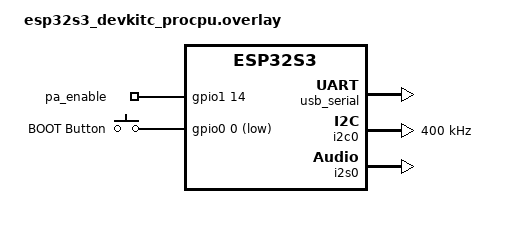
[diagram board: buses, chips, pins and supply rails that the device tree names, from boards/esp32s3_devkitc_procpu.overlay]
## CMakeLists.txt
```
cmake_minimum_required(VERSION 3.20.0)
find_package(Zephyr REQUIRED HINTS $ENV{ZEPHYR_BASE})
project(voice_assistant)

target_sources(app PRIVATE
    src/main.c
    src/audio.c
    src/base64.c
)
```

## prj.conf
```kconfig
# ── Console ──
CONFIG_PRINTK=y
CONFIG_CONSOLE=y
CONFIG_SERIAL=y
CONFIG_LOG=y
CONFIG_LOG_DEFAULT_LEVEL=3
CONFIG_LOG_BUFFER_SIZE=8192

# ── GPIO (PA enable + BOOT button) ──
CONFIG_GPIO=y

# ── I2C (ES8311 + ES7210 register config) ──
CONFIG_I2C=y

# ── I2S (audio TX/RX) + DMA ──
CONFIG_I2S=y
CONFIG_DMA=y

# ── Networking ──
CONFIG_NETWORKING=y
CONFIG_NET_MGMT=y
CONFIG_NET_MGMT_EVENT_INFO=y
CONFIG_NET_IPV4=y
CONFIG_NET_IPV6=n
CONFIG_NET_TCP=y
CONFIG_NET_DHCPV4=y
CONFIG_NET_SOCKETS=y
CONFIG_POSIX_API=y

# ── WiFi ──
CONFIG_WIFI=y
CONFIG_WIFI_NM=y
CONFIG_NET_L2_WIFI_MGMT=y
CONFIG_ESP32_WIFI_STA_AUTO_DHCPV4=y

# ── DNS ──
CONFIG_DNS_RESOLVER=y
CONFIG_DNS_RESOLVER_AI_MAX_ENTRIES=2

# ── HTTP client ──
CONFIG_HTTP_CLIENT=y

# ── TLS / mbedTLS ──
CONFIG_MBEDTLS=y
CONFIG_MBEDTLS_BUILTIN=y
CONFIG_MBEDTLS_ENABLE_HEAP=y
CONFIG_MBEDTLS_HEAP_SIZE=65536
CONFIG_MBEDTLS_SSL_MAX_CONTENT_LEN=16384
CONFIG_MBEDTLS_CIPHER_GCM_ENABLED=y
CONFIG_MBEDTLS_KEY_EXCHANGE_ECDHE_RSA_ENABLED=y
CONFIG_MBEDTLS_KEY_EXCHANGE_RSA_ENABLED=y
CONFIG_MBEDTLS_ECP_DP_SECP256R1_ENABLED=y
CONFIG_MBEDTLS_ECP_DP_SECP384R1_ENABLED=y
CONFIG_MBEDTLS_ECDH_C=y
CONFIG_MBEDTLS_ECP_C=y
CONFIG_NET_SOCKETS_SOCKOPT_TLS=y
CONFIG_NET_SOCKETS_TLS_MAX_CONTEXTS=2
# SNI + GCM required by Alibaba Cloud CDN
CONFIG_MBEDTLS_SERVER_NAME_INDICATION=y

# ── Stack & buffers ──
CONFIG_MAIN_STACK_SIZE=12288
CONFIG_SYSTEM_WORKQUEUE_STACK_SIZE=4096
CONFIG_NET_TX_STACK_SIZE=2048
CONFIG_NET_RX_STACK_SIZE=2048
CONFIG_NET_PKT_RX_COUNT=16
CONFIG_NET_PKT_TX_COUNT=16
CONFIG_NET_BUF_RX_COUNT=64
CONFIG_NET_BUF_TX_COUNT=64
CONFIG_NET_MAX_CONTEXTS=8
CONFIG_NET_MGMT_EVENT_QUEUE_TIMEOUT=5000
CONFIG_NET_MGMT_EVENT_QUEUE_SIZE=16

# ── Heap ──
CONFIG_HEAP_MEM_POOL_SIZE=32768
```

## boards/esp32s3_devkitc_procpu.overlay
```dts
/* Voice Assistant: ES8311 DAC + ES7210 ADC + PA + BOOT Button + USB Console
 *
 * I2C0 — ES8311 (0x18) + ES7210 (0x40) register config (SCL=IO18, SDA=IO8)
 * I2S0 — Audio TX (speaker via ES8311) + RX (mic via ES7210)
 *         MCLK=IO2, BCLK=IO17, WS=IO45, DOUT=IO15, DIN=IO16
 * PA   — GPIO46 (gpio1 pin 14), active-high
 * BOOT — GPIO0 (gpio0 pin 0), active-low, push-to-talk
 */

#include <zephyr/dt-bindings/pinctrl/esp32s3-pinctrl.h>
#include <zephyr/dt-bindings/pinctrl/esp-pinctrl-common.h>
#include <dt-bindings/pinctrl/esp32s3-pinctrl.h>
#include <zephyr/dt-bindings/pinctrl/esp32s3-gpio-sigmap.h>

/ {
	chosen {
		zephyr,console = &usb_serial;
		zephyr,shell-uart = &usb_serial;
	};

	leds {
		compatible = "gpio-leds";
		pa_enable: pa {
			gpios = <&gpio1 14 GPIO_ACTIVE_HIGH>;
		};
	};

	buttons {
		compatible = "gpio-keys";
		boot_button: boot_button {
			gpios = <&gpio0 0 (GPIO_PULL_UP | GPIO_ACTIVE_LOW)>;
			label = "BOOT Button";
		};
	};

	aliases {
		sw0 = &boot_button;
	};
};

&usb_serial {
	status = "okay";
};

&pinctrl {
	i2c0_default: i2c0_default {
		group1 {
			pinmux = <I2C0_SDA_GPIO8>,
				 <I2C0_SCL_GPIO18>;
			bias-pull-up;
			drive-open-drain;
			output-high;
		};
	};

	i2s0_default: i2s0_default {
		group1 {
			pinmux = <I2S0_MCLK_GPIO2>,
				 <I2S0_O_WS_GPIO45>,
				 <I2S0_O_BCK_GPIO17>,
				 <I2S0_O_SD_GPIO15>;
			output-enable;
		};
		group2 {
			pinmux = <I2S0_I_SD_GPIO16>;
			input-enable;
		};
	};
};

&i2c0 {
	status = "okay";
	clock-frequency = <I2C_BITRATE_FAST>;
	pinctrl-0 = <&i2c0_default>;
	pinctrl-names = "default";
};

i2s_rxtx: &i2s0 {
	pinctrl-0 = <&i2s0_default>;
	pinctrl-names = "default";
	status = "okay";
};

&dma {
	status = "okay";
};
```

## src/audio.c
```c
/*
 * audio.c — ES8311 DAC + ES7210 ADC initialization, I2S record & playback
 *
 * ES8311 (0x18): DAC for speaker output via I2S TX
 * ES7210 (0x40): ADC for microphone input via I2S RX
 * I2S0: shared bus, master mode (generates MCLK/BCLK/WS)
 * PA: GPIO46 (gpio1 pin 14), controls speaker amplifier
 */

#include <zephyr/kernel.h>
#include <zephyr/device.h>
#include <zephyr/drivers/i2c.h>
#include <zephyr/drivers/i2s.h>
#include <zephyr/drivers/gpio.h>
#include <zephyr/logging/log.h>
#include <string.h>

#include "audio.h"

LOG_MODULE_REGISTER(audio, LOG_LEVEL_INF);

/* ── ES8311 registers ── */
#define ES8311_ADDR              0x18
#define ES8311_RESET_REG00       0x00
#define ES8311_CLK_MANAGER_REG01 0x01
#define ES8311_CLK_MANAGER_REG02 0x02
#define ES8311_CLK_MANAGER_REG03 0x03
#define ES8311_CLK_MANAGER_REG04 0x04
#define ES8311_CLK_MANAGER_REG05 0x05
#define ES8311_CLK_MANAGER_REG06 0x06
#define ES8311_CLK_MANAGER_REG07 0x07
#define ES8311_CLK_MANAGER_REG08 0x08
#define ES8311_SDPIN_REG09       0x09
#define ES8311_SDPOUT_REG0A      0x0A
#define ES8311_SYSTEM_REG0D      0x0D
#define ES8311_SYSTEM_REG0E      0x0E
#define ES8311_SYSTEM_REG12      0x12
#define ES8311_SYSTEM_REG13      0x13
#define ES8311_ADC_REG16         0x16
#define ES8311_ADC_REG1C         0x1C
#define ES8311_DAC_REG31         0x31
#define ES8311_DAC_REG32         0x32
#define ES8311_DAC_REG37         0x37
#define ES8311_CHIPID1_REG_FD    0xFD
#define ES8311_CHIPID2_REG_FE    0xFE

/* ── ES7210 registers ── */
#define ES7210_ADDR                 0x40
#define ES7210_RESET_REG00          0x00
#define ES7210_CLOCK_OFF_REG01      0x01
#define ES7210_MAINCLK_REG02        0x02
#define ES7210_LRCK_DIVH_REG04      0x04
#define ES7210_LRCK_DIVL_REG05      0x05
#define ES7210_POWER_DOWN_REG06     0x06
#define ES7210_OSR_REG07            0x07
#define ES7210_TIME_CONTROL0_REG09  0x09
#define ES7210_TIME_CONTROL1_REG0A  0x0A
#define ES7210_SDP_INTERFACE1_REG11 0x11
#define ES7210_SDP_INTERFACE2_REG12 0x12
#define ES7210_ADC12_HPF2_REG22     0x22
#define ES7210_ADC12_HPF1_REG23     0x23
#define ES7210_ADC34_HPF2_REG20     0x20
#define ES7210_ADC34_HPF1_REG21     0x21
#define ES7210_ANALOG_REG40         0x40
#define ES7210_MIC12_BIAS_REG41     0x41
#define ES7210_MIC34_BIAS_REG42     0x42
#define ES7210_MIC1_GAIN_REG43      0x43
#define ES7210_MIC2_GAIN_REG44      0x44
#define ES7210_MIC3_GAIN_REG45      0x45
#define ES7210_MIC4_GAIN_REG46      0x46
#define ES7210_MIC1_POWER_REG47     0x47
#define ES7210_MIC2_POWER_REG48     0x48
#define ES7210_MIC3_POWER_REG49     0x49
#define ES7210_MIC4_POWER_REG4A     0x4A
#define ES7210_MIC12_POWER_REG4B    0x4B
#define ES7210_MIC34_POWER_REG4C    0x4C

/* ── I2S config ── */
#define I2S_NODE          DT_NODELABEL(i2s_rxtx)
#define SAMPLES_PER_BLOCK ((RECORD_SAMPLE_RATE / 100) * NUM_CHANNELS)  /* 320 */
#define BLOCK_SIZE        (SAMPLES_PER_BLOCK * sizeof(int16_t))        /* 640 */
#define BLOCK_COUNT       12

K_MEM_SLAB_DEFINE_STATIC(tx_mem_slab, BLOCK_SIZE, BLOCK_COUNT, 4);
K_MEM_SLAB_DEFINE_STATIC(rx_mem_slab, BLOCK_SIZE, BLOCK_COUNT, 4);

/* ── PA GPIO ── */
static const struct gpio_dt_spec pa_gpio =
	GPIO_DT_SPEC_GET(DT_NODELABEL(pa_enable), gpios);

/* ── Devices ── */
static const struct device *i2c_dev;
static const struct device *i2s_dev;

/* ── I2C helpers ── */
static int es8311_write_reg(uint8_t reg, uint8_t val)
{
	uint8_t buf[2] = {reg, val};
	return i2c_write(i2c_dev, buf, 2, ES8311_ADDR);
}

static int es7210_write_reg(uint8_t reg, uint8_t val)
{
	uint8_t buf[2] = {reg, val};
	return i2c_write(i2c_dev, buf, 2, ES7210_ADDR);
}

/* ── ES8311 init: 16kHz, 16-bit, I2S slave, MCLK=4.096MHz ── */
static int es8311_init(void)
{
	int ret;

	/* Reset — must go through 0x1F → 0x00 → 0x80 sequence */
	ret = es8311_write_reg(ES8311_RESET_REG00, 0x1F);
	if (ret) return ret;
	k_msleep(20);
	ret = es8311_write_reg(ES8311_RESET_REG00, 0x00);
	if (ret) return ret;
	k_msleep(20);
	ret = es8311_write_reg(ES8311_RESET_REG00, 0x80);
	if (ret) return ret;

	/* Clock config — match known-working es8311_test/nes_emulator values
	 * MCLK from external pin, BCLK from MCLK, dividers for 16kHz */
	ret = es8311_write_reg(ES8311_CLK_MANAGER_REG01, 0x3F);
	if (ret) return ret;
	ret = es8311_write_reg(ES8311_CLK_MANAGER_REG02, 0x00);
	if (ret) return ret;
	ret = es8311_write_reg(ES8311_CLK_MANAGER_REG03, 0x10);
	if (ret) return ret;
	ret = es8311_write_reg(ES8311_CLK_MANAGER_REG04, 0x10);
	if (ret) return ret;
	ret = es8311_write_reg(ES8311_CLK_MANAGER_REG05, 0x00);
	if (ret) return ret;
	ret = es8311_write_reg(ES8311_ADC_REG16, 0x24);
	if (ret) return ret;
	ret = es8311_write_reg(ES8311_CLK_MANAGER_REG06, 0x03);
	if (ret) return ret;
	ret = es8311_write_reg(ES8311_CLK_MANAGER_REG07, 0x00);
	if (ret) return ret;
	ret = es8311_write_reg(ES8311_CLK_MANAGER_REG08, 0xFF);
	if (ret) return ret;

	/* I2S format: slave mode, 16-bit */
	ret = es8311_write_reg(ES8311_SDPIN_REG09, 0x0C);
	if (ret) return ret;
	ret = es8311_write_reg(ES8311_SDPOUT_REG0A, 0x0C);
	if (ret) return ret;

	/* Power up analog */
	ret = es8311_write_reg(ES8311_SYSTEM_REG0D, 0x01);
	if (ret) return ret;
	ret = es8311_write_reg(ES8311_SYSTEM_REG0E, 0x02);
	if (ret) return ret;
	ret = es8311_write_reg(ES8311_SYSTEM_REG12, 0x00);
	if (ret) return ret;
	ret = es8311_write_reg(ES8311_SYSTEM_REG13, 0x10);
	if (ret) return ret;

	/* ADC EQ bypass, cancel DC offset */
	ret = es8311_write_reg(ES8311_ADC_REG1C, 0x6A);
	if (ret) return ret;

	/* Bypass DAC equalizer */
	ret = es8311_write_reg(ES8311_DAC_REG37, 0x08);
	if (ret) return ret;

	/* DAC volume ~80% */
	ret = es8311_write_reg(ES8311_DAC_REG32, 0xC0);
	if (ret) return ret;

	/* Unmute DAC */
	ret = es8311_write_reg(ES8311_DAC_REG31, 0x00);
	if (ret) return ret;

	return 0;
}

/* ── ES7210 init: 16kHz, 16-bit, 4-ch ADC, MIC gain 30dB ── */
static int es7210_init(void)
{
	int ret;

	/* Software reset */
	ret = es7210_write_reg(ES7210_RESET_REG00, 0xFF);
	if (ret) return ret;
	ret = es7210_write_reg(ES7210_RESET_REG00, 0x32);
	if (ret) return ret;

	/* Power-up timing */
	ret = es7210_write_reg(ES7210_TIME_CONTROL0_REG09, 0x30);
	if (ret) return ret;
	ret = es7210_write_reg(ES7210_TIME_CONTROL1_REG0A, 0x30);
	if (ret) return ret;

	/* HPF config */
	ret = es7210_write_reg(ES7210_ADC12_HPF1_REG23, 0x2A);
	if (ret) return ret;
	ret = es7210_write_reg(ES7210_ADC12_HPF2_REG22, 0x0A);
	if (ret) return ret;
	ret = es7210_write_reg(ES7210_ADC34_HPF1_REG21, 0x2A);
	if (ret) return ret;
	ret = es7210_write_reg(ES7210_ADC34_HPF2_REG20, 0x0A);
	if (ret) return ret;

	/* I2S format: 16-bit, standard I2S */
	ret = es7210_write_reg(ES7210_SDP_INTERFACE1_REG11, 0x60);
	if (ret) return ret;
	ret = es7210_write_reg(ES7210_SDP_INTERFACE2_REG12, 0x00);
	if (ret) return ret;

	/* Analog power */
	ret = es7210_write_reg(ES7210_ANALOG_REG40, 0xC3);
	if (ret) return ret;

	/* MIC bias 2.87V */
	ret = es7210_write_reg(ES7210_MIC12_BIAS_REG41, 0x70);
	if (ret) return ret;
	ret = es7210_write_reg(ES7210_MIC34_BIAS_REG42, 0x70);
	if (ret) return ret;

	/* MIC gain 30dB */
	ret = es7210_write_reg(ES7210_MIC1_GAIN_REG43, 0x1A);
	if (ret) return ret;
	ret = es7210_write_reg(ES7210_MIC2_GAIN_REG44, 0x1A);
	if (ret) return ret;
	ret = es7210_write_reg(ES7210_MIC3_GAIN_REG45, 0x1A);
	if (ret) return ret;
	ret = es7210_write_reg(ES7210_MIC4_GAIN_REG46, 0x1A);
	if (ret) return ret;

	/* Power on MIC1-4 */
	ret = es7210_write_reg(ES7210_MIC1_POWER_REG47, 0x08);
	if (ret) return ret;
	ret = es7210_write_reg(ES7210_MIC2_POWER_REG48, 0x08);
	if (ret) return ret;
	ret = es7210_write_reg(ES7210_MIC3_POWER_REG49, 0x08);
	if (ret) return ret;
	ret = es7210_write_reg(ES7210_MIC4_POWER_REG4A, 0x08);
	if (ret) return ret;

	/* Clock: MCLK=4096000, fs=16000 */
	ret = es7210_write_reg(ES7210_OSR_REG07, 0x20);
	if (ret) return ret;
	ret = es7210_write_reg(ES7210_MAINCLK_REG02, 0xC1);
	if (ret) return ret;
	ret = es7210_write_reg(ES7210_LRCK_DIVH_REG04, 0x01);
	if (ret) return ret;
	ret = es7210_write_reg(ES7210_LRCK_DIVL_REG05, 0x00);
	if (ret) return ret;

	/* Power down DLL */
	ret = es7210_write_reg(ES7210_POWER_DOWN_REG06, 0x04);
	if (ret) return ret;

	/* Power on MIC bias & ADC & PGA */
	ret = es7210_write_reg(ES7210_MIC12_POWER_REG4B, 0x0F);
	if (ret) return ret;
	ret = es7210_write_reg(ES7210_MIC34_POWER_REG4C, 0x0F);
	if (ret) return ret;

	/* Enable device */
	ret = es7210_write_reg(ES7210_RESET_REG00, 0x71);
	if (ret) return ret;
	ret = es7210_write_reg(ES7210_RESET_REG00, 0x41);
	if (ret) return ret;

	return 0;
}

/* ================================================================
 *  Public API
 * ================================================================ */

/* ── I2S configured once flag ── */
static bool i2s_configured;

int audio_codec_init(void)
{
	int ret;

	/* I2C */
	i2c_dev = DEVICE_DT_GET(DT_NODELABEL(i2c0));
	if (!device_is_ready(i2c_dev)) {
		LOG_ERR("I2C device not ready");
		return -ENODEV;
	}

	/* I2S */
	i2s_dev = DEVICE_DT_GET(I2S_NODE);
	if (!device_is_ready(i2s_dev)) {
		LOG_ERR("I2S device not ready");
		return -ENODEV;
	}

	/* ES8311 DAC */
	ret = es8311_init();
	if (ret) {
		LOG_ERR("ES8311 init failed: %d", ret);
		return ret;
	}
	LOG_INF("ES8311 DAC initialized");

	/* ES7210 ADC */
	ret = es7210_init();
	if (ret) {
		LOG_ERR("ES7210 init failed: %d", ret);
		return ret;
	}
	LOG_INF("ES7210 ADC initialized");

	/* PA GPIO */
	if (!gpio_is_ready_dt(&pa_gpio)) {
		LOG_ERR("PA GPIO not ready");
		return -ENODEV;
	}
	ret = gpio_pin_configure_dt(&pa_gpio, GPIO_OUTPUT_INACTIVE);
	if (ret) {
		LOG_ERR("PA GPIO config failed: %d", ret);
		return ret;
	}

	/* Configure I2S TX + RX once — both share 16kHz, 16-bit, stereo */
	struct i2s_config tx_cfg = {
		.word_size = SAMPLE_BITS,
		.channels = NUM_CHANNELS,
		.format = I2S_FMT_DATA_FORMAT_I2S,
		.options = I2S_OPT_BIT_CLK_MASTER | I2S_OPT_FRAME_CLK_MASTER,
		.frame_clk_freq = RECORD_SAMPLE_RATE,
		.mem_slab = &tx_mem_slab,
		.block_size = BLOCK_SIZE,
		.timeout = 1000,
	};
	ret = i2s_configure(i2s_dev, I2S_DIR_TX, &tx_cfg);
	if (ret) {
		LOG_ERR("I2S TX config failed: %d", ret);
		return ret;
	}

	struct i2s_config rx_cfg = {
		.word_size = SAMPLE_BITS,
		.channels = NUM_CHANNELS,
		.format = I2S_FMT_DATA_FORMAT_I2S,
		.options = I2S_OPT_BIT_CLK_MASTER | I2S_OPT_FRAME_CLK_MASTER,
		.frame_clk_freq = RECORD_SAMPLE_RATE,
		.mem_slab = &rx_mem_slab,
		.block_size = BLOCK_SIZE,
		.timeout = 2000,
	};
	ret = i2s_configure(i2s_dev, I2S_DIR_RX, &rx_cfg);
	if (ret) {
		LOG_ERR("I2S RX config failed: %d", ret);
		return ret;
	}

	i2s_configured = true;
	LOG_INF("Audio codecs ready (16kHz, 16-bit)");
	return 0;
}

void audio_pa_enable(int on)
{
	gpio_pin_set_dt(&pa_gpio, on ? 1 : 0);
}

int audio_record(int16_t *pcm_buf, int max_samples, volatile bool *stop_flag)
{
	int ret;
	int mono_idx = 0;

	/* Full I2S reset sequence — critical for preventing DMA crashes
	 * after play→record transitions on ESP32-S3 */
	i2s_trigger(i2s_dev, I2S_DIR_TX, I2S_TRIGGER_PREPARE);  /* recover from ERROR if needed */
	i2s_trigger(i2s_dev, I2S_DIR_RX, I2S_TRIGGER_PREPARE);
	i2s_trigger(i2s_dev, I2S_DIR_RX, I2S_TRIGGER_DROP);
	i2s_trigger(i2s_dev, I2S_DIR_TX, I2S_TRIGGER_DROP);
	k_msleep(100);

	/* Reinitialize mem slabs — repairs any DMA-related free list corruption */
	k_mem_slab_init(&tx_mem_slab, tx_mem_slab.buffer, BLOCK_SIZE, BLOCK_COUNT);
	k_mem_slab_init(&rx_mem_slab, rx_mem_slab.buffer, BLOCK_SIZE, BLOCK_COUNT);

	/* Re-configure both directions (resets DMA descriptors) */
	struct i2s_config tx_cfg = {
		.word_size = SAMPLE_BITS,
		.channels = NUM_CHANNELS,
		.format = I2S_FMT_DATA_FORMAT_I2S,
		.options = I2S_OPT_BIT_CLK_MASTER | I2S_OPT_FRAME_CLK_MASTER,
		.frame_clk_freq = RECORD_SAMPLE_RATE,
		.mem_slab = &tx_mem_slab,
		.block_size = BLOCK_SIZE,
		.timeout = 1000,
	};
	ret = i2s_configure(i2s_dev, I2S_DIR_TX, &tx_cfg);
	if (ret && ret != -EBUSY) {
		LOG_ERR("I2S TX reconfig failed: %d", ret);
	}

	struct i2s_config rx_cfg = {
		.word_size = SAMPLE_BITS,
		.channels = NUM_CHANNELS,
		.format = I2S_FMT_DATA_FORMAT_I2S,
		.options = I2S_OPT_BIT_CLK_MASTER | I2S_OPT_FRAME_CLK_MASTER,
		.frame_clk_freq = RECORD_SAMPLE_RATE,
		.mem_slab = &rx_mem_slab,
		.block_size = BLOCK_SIZE,
		.timeout = 2000,
	};
	ret = i2s_configure(i2s_dev, I2S_DIR_RX, &rx_cfg);
	if (ret && ret != -EBUSY) {
		LOG_ERR("I2S RX reconfig failed: %d", ret);
	}

	/* Additional settle time for DMA hardware */
	k_msleep(50);

	/* Pre-fill TX with silence for clock generation */
	for (int i = 0; i < 2; i++) {
		void *blk;
		ret = k_mem_slab_alloc(&tx_mem_slab, &blk, K_NO_WAIT);
		if (ret) {
			LOG_ERR("TX block alloc failed");
			return ret;
		}
		memset(blk, 0, BLOCK_SIZE);
		ret = i2s_write(i2s_dev, blk, BLOCK_SIZE);
		if (ret) {
			LOG_ERR("I2S TX write failed: %d", ret);
			return ret;
		}
	}

	/* Start TX then RX */
	ret = i2s_trigger(i2s_dev, I2S_DIR_TX, I2S_TRIGGER_START);
	if (ret) {
		LOG_ERR("I2S TX start failed: %d", ret);
		return ret;
	}
	ret = i2s_trigger(i2s_dev, I2S_DIR_RX, I2S_TRIGGER_START);
	if (ret) {
		LOG_ERR("I2S RX start failed: %d", ret);
		return ret;
	}

	LOG_INF("Recording started...");

	/* Read blocks until stop_flag or max_samples reached */
	while (!(*stop_flag) && mono_idx < max_samples) {
		void *rx_blk;
		size_t rx_sz;
		void *tx_blk;

		/* Feed TX with silence to keep clocks running */
		if (k_mem_slab_alloc(&tx_mem_slab, &tx_blk, K_NO_WAIT) == 0) {
			memset(tx_blk, 0, BLOCK_SIZE);
			if (i2s_write(i2s_dev, tx_blk, BLOCK_SIZE) < 0) {
				k_mem_slab_free(&tx_mem_slab, tx_blk);
			}
		}

		/* Read one block of stereo data */
		ret = i2s_read(i2s_dev, &rx_blk, &rx_sz);
		if (ret) {
			LOG_WRN("I2S read error: %d", ret);
			break;
		}

		/* Extract left channel (mono) from interleaved stereo */
		int16_t *stereo = (int16_t *)rx_blk;
		int stereo_samples = rx_sz / sizeof(int16_t);
		for (int i = 0; i < stereo_samples && mono_idx < max_samples; i += 2) {
			pcm_buf[mono_idx++] = stereo[i];  /* left channel */
		}

		k_mem_slab_free(&rx_mem_slab, rx_blk);
	}

	/* Stop I2S */
	i2s_trigger(i2s_dev, I2S_DIR_RX, I2S_TRIGGER_DROP);
	i2s_trigger(i2s_dev, I2S_DIR_TX, I2S_TRIGGER_DROP);

	/* Allow DMA to settle */
	k_msleep(100);

	/* Drain any remaining RX blocks */
	while (1) {
		void *blk;
		size_t sz;
		if (i2s_read(i2s_dev, &blk, &sz) != 0) break;
		k_mem_slab_free(&rx_mem_slab, blk);
	}

	LOG_INF("Recording stopped: %d samples (%.1fs)",
		mono_idx, (float)mono_idx / RECORD_SAMPLE_RATE);

	return mono_idx;
}

int audio_play(const int16_t *pcm_buf, int num_samples)
{
	int ret;

	/* Stop any previous I2S activity */
	i2s_trigger(i2s_dev, I2S_DIR_RX, I2S_TRIGGER_DROP);
	i2s_trigger(i2s_dev, I2S_DIR_TX, I2S_TRIGGER_DROP);
	k_msleep(50);

	/* Re-configure I2S TX */
	struct i2s_config tx_cfg = {
		.word_size = SAMPLE_BITS,
		.channels = NUM_CHANNELS,
		.format = I2S_FMT_DATA_FORMAT_I2S,
		.options = I2S_OPT_BIT_CLK_MASTER | I2S_OPT_FRAME_CLK_MASTER,
		.frame_clk_freq = PLAYBACK_SAMPLE_RATE,
		.mem_slab = &tx_mem_slab,
		.block_size = BLOCK_SIZE,
		.timeout = 1000,
	};
	ret = i2s_configure(i2s_dev, I2S_DIR_TX, &tx_cfg);
	if (ret) {
		LOG_ERR("I2S TX reconfig failed: %d", ret);
		return ret;
	}

	audio_pa_enable(1);

	/* Mono samples per block (stereo block has SAMPLES_PER_BLOCK/2 mono) */
	int mono_per_block = SAMPLES_PER_BLOCK / NUM_CHANNELS;  /* 160 */
	int pcm_idx = 0;
	int blocks_written = 0;

	/* Pre-fill 2 blocks */
	for (int pf = 0; pf < 2 && pcm_idx < num_samples; pf++) {
		void *blk;
		ret = k_mem_slab_alloc(&tx_mem_slab, &blk, K_NO_WAIT);
		if (ret) {
			LOG_ERR("TX block alloc failed");
			audio_pa_enable(0);
			return ret;
		}
		int16_t *out = (int16_t *)blk;
		int count = 0;
		while (count < mono_per_block && pcm_idx < num_samples) {
			out[count * 2] = pcm_buf[pcm_idx];      /* Left */
			out[count * 2 + 1] = pcm_buf[pcm_idx];  /* Right */
			pcm_idx++;
			count++;
		}
		/* Zero-fill remainder if not enough samples */
		while (count < mono_per_block) {
			out[count * 2] = 0;
			out[count * 2 + 1] = 0;
			count++;
		}
		ret = i2s_write(i2s_dev, blk, BLOCK_SIZE);
		if (ret) {
			LOG_ERR("I2S write failed");
			k_mem_slab_free(&tx_mem_slab, blk);
			audio_pa_enable(0);
			return ret;
		}
		blocks_written++;
	}

	/* Start TX */
	ret = i2s_trigger(i2s_dev, I2S_DIR_TX, I2S_TRIGGER_START);
	if (ret) {
		LOG_ERR("I2S TX start failed: %d", ret);
		audio_pa_enable(0);
		return ret;
	}

	LOG_INF("Playing %d samples (%.1fs)...",
		num_samples, (float)num_samples / PLAYBACK_SAMPLE_RATE);

	/* Continue feeding blocks */
	while (pcm_idx < num_samples) {
		void *blk;
		ret = k_mem_slab_alloc(&tx_mem_slab, &blk, K_MSEC(500));
		if (ret) {
			LOG_WRN("TX alloc timeout");
			continue;
		}
		int16_t *out = (int16_t *)blk;
		int count = 0;
		while (count < mono_per_block && pcm_idx < num_samples) {
			out[count * 2] = pcm_buf[pcm_idx];
			out[count * 2 + 1] = pcm_buf[pcm_idx];
			pcm_idx++;
			count++;
		}
		while (count < mono_per_block) {
			out[count * 2] = 0;
			out[count * 2 + 1] = 0;
			count++;
		}
		ret = i2s_write(i2s_dev, blk, BLOCK_SIZE);
		if (ret) {
			k_mem_slab_free(&tx_mem_slab, blk);
			break;
		}
		blocks_written++;
	}

	/* Let last blocks drain, then stop */
	k_msleep(200);
	i2s_trigger(i2s_dev, I2S_DIR_TX, I2S_TRIGGER_DROP);
	k_msleep(50);
	audio_pa_enable(0);

	LOG_INF("Playback complete: %d blocks", blocks_written);
	return 0;
}

/* ================================================================
 *  Streaming accumulate-then-play
 *
 *  SSE chunks are decoded and resampled in real-time as they arrive
 *  (saving decode time), but playback only starts after all data is
 *  received.  This avoids I2S underrun caused by network delivery
 *  being slower than real-time playback rate.
 * ================================================================ */

static volatile int stream_write_idx;   /* mono samples accumulated so far */
static volatile bool stream_active;     /* accumulation in progress */
static int16_t *stream_buf;            /* pointer to playback_pcm */
static int stream_buf_max;              /* max samples in buffer */

int audio_stream_start(void)
{
	if (stream_active) {
		LOG_WRN("Stream already active");
		return -EBUSY;
	}

	stream_write_idx = 0;
	stream_active = true;

	extern int16_t playback_pcm[];
	stream_buf = playback_pcm;
	stream_buf_max = MAX_PLAYBACK_SAMPLES;

	return 0;
}

int audio_stream_feed(const int16_t *samples, int count)
{
	if (!stream_active) return -EINVAL;

	int space = stream_buf_max - stream_write_idx;
	if (count > space) count = space;
	if (count <= 0) return 0;

	memcpy(&stream_buf[stream_write_idx], samples, count * sizeof(int16_t));
	stream_write_idx += count;

	return count;
}

int audio_stream_stop(void)
{
	if (!stream_active) return 0;

	stream_active = false;

	/* Play all accumulated audio */
	if (stream_write_idx > 0) {
		LOG_INF("Playing %d accumulated samples (%.1fs)",
			stream_write_idx,
			(float)stream_write_idx / PLAYBACK_SAMPLE_RATE);
		audio_play(stream_buf, stream_write_idx);
	}

	/* Reinitialize mem slabs for clean state before next recording */
	k_mem_slab_init(&tx_mem_slab, tx_mem_slab.buffer, BLOCK_SIZE, BLOCK_COUNT);
	k_mem_slab_init(&rx_mem_slab, rx_mem_slab.buffer, BLOCK_SIZE, BLOCK_COUNT);

	return 0;
}

int audio_resample_24k_to_16k(const int16_t *in, int in_samples,
			      int16_t *out, int max_out)
{
	/* 24kHz → 16kHz = ratio 3:2
	 * For every 3 input samples, output 2 using linear interpolation.
	 * Output position i maps to input position i * 1.5
	 */
	int out_samples = (in_samples * 2) / 3;
	if (out_samples > max_out) {
		out_samples = max_out;
	}

	for (int i = 0; i < out_samples; i++) {
		/* Fixed-point: input position = i * 3 / 2 */
		int pos_x2 = i * 3;  /* position * 2 */
		int idx = pos_x2 / 2;
		int frac = pos_x2 % 2;  /* 0 or 1 (fraction * 2) */

		if (idx + 1 < in_samples && frac) {
			/* Linear interpolation: (in[idx] + in[idx+1]) / 2 */
			out[i] = (int16_t)(((int32_t)in[idx] + in[idx + 1]) / 2);
		} else if (idx < in_samples) {
			out[i] = in[idx];
		} else {
			out[i] = 0;
		}
	}

	return out_samples;
}
```

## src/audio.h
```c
/*
 * audio.h — ES8311 DAC + ES7210 ADC + I2S record/playback + streaming
 */
#ifndef AUDIO_H
#define AUDIO_H

#include <stdint.h>
#include <stddef.h>
#include <stdbool.h>

/* Sample rates */
#define RECORD_SAMPLE_RATE   16000
#define PLAYBACK_SAMPLE_RATE 16000   /* resample 24kHz→16kHz before play */
#define SAMPLE_BITS          16
#define NUM_CHANNELS         2       /* I2S stereo; mono extracted in SW */

/* Recording limits */
#define MAX_RECORD_SECONDS   5
#define MAX_RECORD_SAMPLES   (MAX_RECORD_SECONDS * RECORD_SAMPLE_RATE)  /* mono */
#define MAX_RECORD_PCM_BYTES (MAX_RECORD_SAMPLES * sizeof(int16_t))     /* 160000 */

/* Playback limits (after 24kHz→16kHz resample) */
#define MAX_PLAYBACK_SECONDS 15
#define MAX_PLAYBACK_SAMPLES (MAX_PLAYBACK_SECONDS * PLAYBACK_SAMPLE_RATE)
#define MAX_PLAYBACK_PCM_BYTES (MAX_PLAYBACK_SAMPLES * sizeof(int16_t)) /* 480000 */

/* Initialize audio codecs (ES8311 + ES7210) and configure I2S (once). */
int audio_codec_init(void);

/* Enable/disable PA (speaker amplifier) */
void audio_pa_enable(int on);

/* Record mono PCM (16kHz, 16-bit) while button held.
 * Returns number of mono samples recorded, or negative on error. */
int audio_record(int16_t *pcm_buf, int max_samples, volatile bool *stop_flag);

/* Play mono PCM (16kHz, 16-bit) through ES8311 speaker (blocking).
 * Returns 0 on success. */
int audio_play(const int16_t *pcm_buf, int num_samples);

/* ── Streaming playback API ── */

/* Begin streaming playback. Enables PA and starts I2S TX thread.
 * Call audio_stream_feed() to push samples, then audio_stream_stop(). */
int audio_stream_start(void);

/* Feed 16kHz mono PCM samples into the streaming playback buffer.
 * Can be called from any thread while stream is active.
 * Returns number of samples actually consumed (<= count if buffer is full). */
int audio_stream_feed(const int16_t *samples, int count);

/* Signal that no more data will be fed. Waits for remaining audio to play out. */
int audio_stream_stop(void);

/* Resample 24kHz mono → 16kHz mono (simple linear interpolation).
 * Returns number of output samples. */
int audio_resample_24k_to_16k(const int16_t *in, int in_samples,
			      int16_t *out, int max_out);

#endif /* AUDIO_H */
```

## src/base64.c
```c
/*
 * base64.c — Base64 encode/decode
 */

#include "base64.h"

static const char b64_enc_table[] =
	"ABCDEFGHIJKLMNOPQRSTUVWXYZabcdefghijklmnopqrstuvwxyz0123456789+/";

static const uint8_t b64_dec_table[256] = {
	['A'] = 0,  ['B'] = 1,  ['C'] = 2,  ['D'] = 3,  ['E'] = 4,
	['F'] = 5,  ['G'] = 6,  ['H'] = 7,  ['I'] = 8,  ['J'] = 9,
	['K'] = 10, ['L'] = 11, ['M'] = 12, ['N'] = 13, ['O'] = 14,
	['P'] = 15, ['Q'] = 16, ['R'] = 17, ['S'] = 18, ['T'] = 19,
	['U'] = 20, ['V'] = 21, ['W'] = 22, ['X'] = 23, ['Y'] = 24,
	['Z'] = 25, ['a'] = 26, ['b'] = 27, ['c'] = 28, ['d'] = 29,
	['e'] = 30, ['f'] = 31, ['g'] = 32, ['h'] = 33, ['i'] = 34,
	['j'] = 35, ['k'] = 36, ['l'] = 37, ['m'] = 38, ['n'] = 39,
	['o'] = 40, ['p'] = 41, ['q'] = 42, ['r'] = 43, ['s'] = 44,
	['t'] = 45, ['u'] = 46, ['v'] = 47, ['w'] = 48, ['x'] = 49,
	['y'] = 50, ['z'] = 51, ['0'] = 52, ['1'] = 53, ['2'] = 54,
	['3'] = 55, ['4'] = 56, ['5'] = 57, ['6'] = 58, ['7'] = 59,
	['8'] = 60, ['9'] = 61, ['+'] = 62, ['/'] = 63,
};

size_t base64_encode(const uint8_t *in, size_t in_len,
		     char *out, size_t out_max)
{
	size_t out_len = ((in_len + 2) / 3) * 4;
	if (out_len >= out_max) {
		return 0;
	}

	size_t i, j;
	for (i = 0, j = 0; i + 2 < in_len; i += 3, j += 4) {
		uint32_t v = ((uint32_t)in[i] << 16) |
			     ((uint32_t)in[i + 1] << 8) |
			     (uint32_t)in[i + 2];
		out[j]     = b64_enc_table[(v >> 18) & 0x3F];
		out[j + 1] = b64_enc_table[(v >> 12) & 0x3F];
		out[j + 2] = b64_enc_table[(v >> 6) & 0x3F];
		out[j + 3] = b64_enc_table[v & 0x3F];
	}

	if (i < in_len) {
		uint32_t v = (uint32_t)in[i] << 16;
		if (i + 1 < in_len) {
			v |= (uint32_t)in[i + 1] << 8;
		}
		out[j]     = b64_enc_table[(v >> 18) & 0x3F];
		out[j + 1] = b64_enc_table[(v >> 12) & 0x3F];
		out[j + 2] = (i + 1 < in_len) ? b64_enc_table[(v >> 6) & 0x3F] : '=';
		out[j + 3] = '=';
		j += 4;
	}

	out[j] = '\0';
	return j;
}

int base64_decode(const char *in, size_t in_len,
		  uint8_t *out, size_t out_max)
{
	/* Skip trailing whitespace/newlines */
	while (in_len > 0 && (in[in_len - 1] == '\n' || in[in_len - 1] == '\r' ||
			       in[in_len - 1] == ' ')) {
		in_len--;
	}

	if (in_len == 0 || (in_len % 4) != 0) {
		return -1;
	}

	size_t out_len = (in_len / 4) * 3;
	if (in[in_len - 1] == '=') out_len--;
	if (in[in_len - 2] == '=') out_len--;

	if (out_len > out_max) {
		return -2;
	}

	size_t i, j;
	for (i = 0, j = 0; i < in_len; i += 4) {
		uint32_t a = b64_dec_table[(unsigned char)in[i]];
		uint32_t b = b64_dec_table[(unsigned char)in[i + 1]];
		uint32_t c = b64_dec_table[(unsigned char)in[i + 2]];
		uint32_t d = b64_dec_table[(unsigned char)in[i + 3]];

		uint32_t v = (a << 18) | (b << 12) | (c << 6) | d;

		if (j < out_len) out[j++] = (v >> 16) & 0xFF;
		if (j < out_len) out[j++] = (v >> 8) & 0xFF;
		if (j < out_len) out[j++] = v & 0xFF;
	}

	return (int)out_len;
}
```

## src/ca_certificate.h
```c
/*
 * ca_certificate.h — GlobalSign Root CA - R3 (cross-signed)
 * Used for TLS connection to dashscope.aliyuncs.com
 */
#ifndef CA_CERTIFICATE_H
#define CA_CERTIFICATE_H

#define CA_CERTIFICATE_TAG 1
#define TLS_PEER_HOSTNAME "dashscope.aliyuncs.com"

/* GlobalSign Root CA - R3 (self-signed)
 * Subject: OU=GlobalSign Root CA - R3, O=GlobalSign, CN=GlobalSign
 * Valid:   2009-03-18 to 2029-03-18
 * DER size: 867 bytes
 */
static const unsigned char ca_certificate[] = {
	0x30, 0x82, 0x03, 0x5f, 0x30, 0x82, 0x02, 0x47, 0xa0, 0x03, 0x02, 0x01,
	0x02, 0x02, 0x0b, 0x04, 0x00, 0x00, 0x00, 0x00, 0x01, 0x21, 0x58, 0x53,
	0x08, 0xa2, 0x30, 0x0d, 0x06, 0x09, 0x2a, 0x86, 0x48, 0x86, 0xf7, 0x0d,
	0x01, 0x01, 0x0b, 0x05, 0x00, 0x30, 0x4c, 0x31, 0x20, 0x30, 0x1e, 0x06,
	0x03, 0x55, 0x04, 0x0b, 0x13, 0x17, 0x47, 0x6c, 0x6f, 0x62, 0x61, 0x6c,
	0x53, 0x69, 0x67, 0x6e, 0x20, 0x52, 0x6f, 0x6f, 0x74, 0x20, 0x43, 0x41,
	0x20, 0x2d, 0x20, 0x52, 0x33, 0x31, 0x13, 0x30, 0x11, 0x06, 0x03, 0x55,
	0x04, 0x0a, 0x13, 0x0a, 0x47, 0x6c, 0x6f, 0x62, 0x61, 0x6c, 0x53, 0x69,
	0x67, 0x6e, 0x31, 0x13, 0x30, 0x11, 0x06, 0x03, 0x55, 0x04, 0x03, 0x13,
	0x0a, 0x47, 0x6c, 0x6f, 0x62, 0x61, 0x6c, 0x53, 0x69, 0x67, 0x6e, 0x30,
	0x1e, 0x17, 0x0d, 0x30, 0x39, 0x30, 0x33, 0x31, 0x38, 0x31, 0x30, 0x30,
	0x30, 0x30, 0x30, 0x5a, 0x17, 0x0d, 0x32, 0x39, 0x30, 0x33, 0x31, 0x38,
	0x31, 0x30, 0x30, 0x30, 0x30, 0x30, 0x5a, 0x30, 0x4c, 0x31, 0x20, 0x30,
	0x1e, 0x06, 0x03, 0x55, 0x04, 0x0b, 0x13, 0x17, 0x47, 0x6c, 0x6f, 0x62,
	0x61, 0x6c, 0x53, 0x69, 0x67, 0x6e, 0x20, 0x52, 0x6f, 0x6f, 0x74, 0x20,
	0x43, 0x41, 0x20, 0x2d, 0x20, 0x52, 0x33, 0x31, 0x13, 0x30, 0x11, 0x06,
	0x03, 0x55, 0x04, 0x0a, 0x13, 0x0a, 0x47, 0x6c, 0x6f, 0x62, 0x61, 0x6c,
	0x53, 0x69, 0x67, 0x6e, 0x31, 0x13, 0x30, 0x11, 0x06, 0x03, 0x55, 0x04,
	0x03, 0x13, 0x0a, 0x47, 0x6c, 0x6f, 0x62, 0x61, 0x6c, 0x53, 0x69, 0x67,
	0x6e, 0x30, 0x82, 0x01, 0x22, 0x30, 0x0d, 0x06, 0x09, 0x2a, 0x86, 0x48,
	0x86, 0xf7, 0x0d, 0x01, 0x01, 0x01, 0x05, 0x00, 0x03, 0x82, 0x01, 0x0f,
	0x00, 0x30, 0x82, 0x01, 0x0a, 0x02, 0x82, 0x01, 0x01, 0x00, 0xcc, 0x25,
	0x76, 0x90, 0x79, 0x06, 0x78, 0x22, 0x16, 0xf5, 0xc0, 0x83, 0xb6, 0x84,
	0xca, 0x28, 0x9e, 0xfd, 0x05, 0x76, 0x11, 0xc5, 0xad, 0x88, 0x72, 0xfc,
	0x46, 0x02, 0x43, 0xc7, 0xb2, 0x8a, 0x9d, 0x04, 0x5f, 0x24, 0xcb, 0x2e,
	0x4b, 0xe1, 0x60, 0x82, 0x46, 0xe1, 0x52, 0xab, 0x0c, 0x81, 0x47, 0x70,
	0x6c, 0xdd, 0x64, 0xd1, 0xeb, 0xf5, 0x2c, 0xa3, 0x0f, 0x82, 0x3d, 0x0c,
	0x2b, 0xae, 0x97, 0xd7, 0xb6, 0x14, 0x86, 0x10, 0x79, 0xbb, 0x3b, 0x13,
	0x80, 0x77, 0x8c, 0x08, 0xe1, 0x49, 0xd2, 0x6a, 0x62, 0x2f, 0x1f, 0x5e,
	0xfa, 0x96, 0x68, 0xdf, 0x89, 0x27, 0x95, 0x38, 0x9f, 0x06, 0xd7, 0x3e,
	0xc9, 0xcb, 0x26, 0x59, 0x0d, 0x73, 0xde, 0xb0, 0xc8, 0xe9, 0x26, 0x0e,
	0x83, 0x15, 0xc6, 0xef, 0x5b, 0x8b, 0xd2, 0x04, 0x60, 0xca, 0x49, 0xa6,
	0x28, 0xf6, 0x69, 0x3b, 0xf6, 0xcb, 0xc8, 0x28, 0x91, 0xe5, 0x9d, 0x8a,
	0x61, 0x57, 0x37, 0xac, 0x74, 0x14, 0xdc, 0x74, 0xe0, 0x3a, 0xee, 0x72,
	0x2f, 0x2e, 0x9c, 0xfb, 0xd0, 0xbb, 0xbf, 0xf5, 0x3d, 0x00, 0xe1, 0x06,
	0x33, 0xe8, 0x82, 0x2b, 0xae, 0x53, 0xa6, 0x3a, 0x16, 0x73, 0x8c, 0xdd,
	0x41, 0x0e, 0x20, 0x3a, 0xc0, 0xb4, 0xa7, 0xa1, 0xe9, 0xb2, 0x4f, 0x90,
	0x2e, 0x32, 0x60, 0xe9, 0x57, 0xcb, 0xb9, 0x04, 0x92, 0x68, 0x68, 0xe5,
	0x38, 0x26, 0x60, 0x75, 0xb2, 0x9f, 0x77, 0xff, 0x91, 0x14, 0xef, 0xae,
	0x20, 0x49, 0xfc, 0xad, 0x40, 0x15, 0x48, 0xd1, 0x02, 0x31, 0x61, 0x19,
	0x5e, 0xb8, 0x97, 0xef, 0xad, 0x77, 0xb7, 0x64, 0x9a, 0x7a, 0xbf, 0x5f,
	0xc1, 0x13, 0xef, 0x9b, 0x62, 0xfb, 0x0d, 0x6c, 0xe0, 0x54, 0x69, 0x16,
	0xa9, 0x03, 0xda, 0x6e, 0xe9, 0x83, 0x93, 0x71, 0x76, 0xc6, 0x69, 0x85,
	0x82, 0x17, 0x02, 0x03, 0x01, 0x00, 0x01, 0xa3, 0x42, 0x30, 0x40, 0x30,
	0x0e, 0x06, 0x03, 0x55, 0x1d, 0x0f, 0x01, 0x01, 0xff, 0x04, 0x04, 0x03,
	0x02, 0x01, 0x06, 0x30, 0x0f, 0x06, 0x03, 0x55, 0x1d, 0x13, 0x01, 0x01,
	0xff, 0x04, 0x05, 0x30, 0x03, 0x01, 0x01, 0xff, 0x30, 0x1d, 0x06, 0x03,
	0x55, 0x1d, 0x0e, 0x04, 0x16, 0x04, 0x14, 0x8f, 0xf0, 0x4b, 0x7f, 0xa8,
	0x2e, 0x45, 0x24, 0xae, 0x4d, 0x50, 0xfa, 0x63, 0x9a, 0x8b, 0xde, 0xe2,
	0xdd, 0x1b, 0xbc, 0x30, 0x0d, 0x06, 0x09, 0x2a, 0x86, 0x48, 0x86, 0xf7,
	0x0d, 0x01, 0x01, 0x0b, 0x05, 0x00, 0x03, 0x82, 0x01, 0x01, 0x00, 0x3b,
	0x40, 0x4b, 0x3b, 0x07, 0x60, 0x89, 0x58, 0x3f, 0x12, 0xe0, 0xd8, 0x10,
	0x05, 0x25, 0x4c, 0xec, 0x21, 0x21, 0x54, 0x3e, 0x25, 0xfe, 0xd9, 0x9a,
	0x24, 0x43, 0x0c, 0x14, 0x50, 0x91, 0xa0, 0x84, 0x27, 0x34, 0xc1, 0x5e,
	0x23, 0x9b, 0x6f, 0x44, 0xa5, 0x47, 0xd0, 0x64, 0x91, 0x54, 0x30, 0x0e,
	0x71, 0x59, 0x30, 0x5b, 0x5f, 0x00, 0xad, 0x3e, 0xe2, 0x94, 0x6b, 0x20,
	0xa1, 0x1a, 0x61, 0x23, 0x6e, 0x08, 0xc2, 0x8e, 0x5a, 0x41, 0xcb, 0x96,
	0x32, 0xe1, 0xa8, 0x62, 0x6c, 0x2c, 0x14, 0xef, 0x05, 0x34, 0x84, 0x5e,
	0xaa, 0x52, 0x5e, 0xf6, 0xbc, 0x72, 0x63, 0x8a, 0x4c, 0xca, 0x7d, 0x6f,
	0x23, 0x50, 0xf6, 0xce, 0x15, 0xd3, 0xdd, 0x6c, 0xd7, 0x60, 0x93, 0xc3,
	0xab, 0x89, 0x2a, 0x06, 0x0c, 0x72, 0xa5, 0xd9, 0xfc, 0xe1, 0xda, 0x43,
	0x79, 0x61, 0x3a, 0xeb, 0x34, 0x45, 0x17, 0x56, 0xe5, 0x85, 0x00, 0x3e,
	0xc7, 0xf7, 0x06, 0x32, 0x7a, 0x36, 0x8b, 0xc8, 0x3b, 0x20, 0x15, 0xfe,
	0x73, 0x25, 0xa4, 0xe9, 0x0d, 0x2c, 0xab, 0x3d, 0x3a, 0x29, 0xc5, 0x08,
	0xc5, 0x88, 0x2a, 0x2c, 0x41, 0x57, 0x40, 0x3e, 0xfa, 0xff, 0x16, 0x88,
	0x8d, 0xa1, 0xb1, 0x67, 0xcd, 0xfa, 0xa2, 0x66, 0xcc, 0xf9, 0xa2, 0x42,
	0x4f, 0x65, 0xa9, 0x87, 0x14, 0x18, 0xb1, 0xf8, 0x2c, 0x1c, 0x53, 0x40,
	0x68, 0xbc, 0x05, 0x25, 0xb1, 0xe5, 0xbb, 0x36, 0x6d, 0xd5, 0x72, 0x34,
	0xc5, 0xf5, 0x22, 0x20, 0xd2, 0xb2, 0xdb, 0x3f, 0x7f, 0xce, 0x61, 0x26,
	0x42, 0xcb, 0x6d, 0x80, 0xfb, 0x4e, 0xa9, 0x03, 0x46, 0xf5, 0xcf, 0x43,
	0x1e, 0xbe, 0x7c, 0x21, 0xe4, 0x7b, 0x50, 0x0c, 0xe3, 0xd3, 0xa6, 0x14,
	0x42, 0xde, 0x4b, 0x40, 0x5f, 0xb2, 0x4f, 0xc7, 0x91, 0xe4, 0x35, 0x7b,
	0x97, 0x29, 0xf1, 0x50, 0x48, 0x05, 0x73, 0x01
};

#endif /* CA_CERTIFICATE_H */
```

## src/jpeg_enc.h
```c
#ifndef JPEG_ENC_H
#define JPEG_ENC_H
#include <stdint.h>

/**
 * Encode RGB565 image to JPEG.
 * @param rgb565    Input pixel data (row-major, big-endian RGB565)
 * @param width     Image width (must be > 0)
 * @param height    Image height (must be > 0)
 * @param jpeg_out  Output buffer for JPEG data
 * @param max_out   Size of output buffer
 * @return          Number of bytes written to jpeg_out, or negative on error
 */
int jpeg_encode_rgb565(const uint16_t *rgb565, int width, int height,
                       uint8_t *jpeg_out, int max_out);

#endif
```
